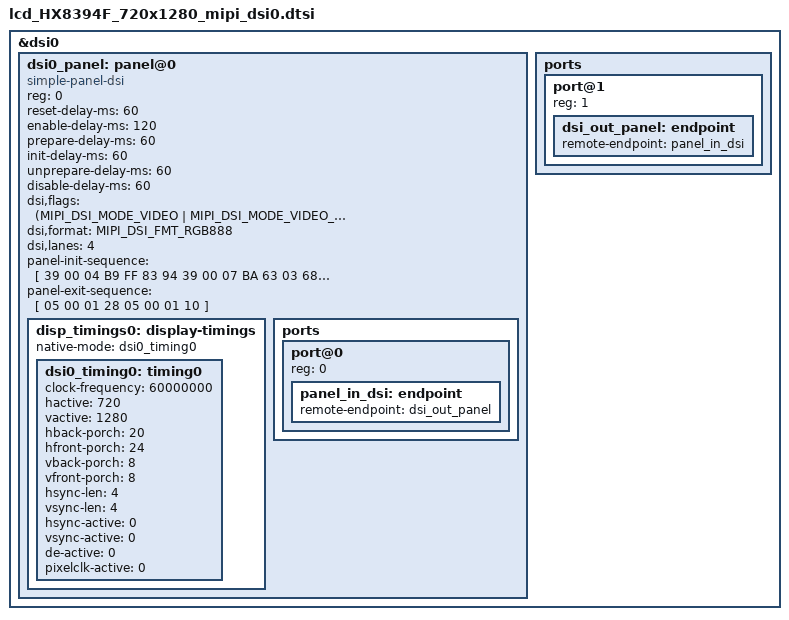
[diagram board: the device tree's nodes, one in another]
#include <dt-bindings/display/drm_mipi_dsi.h>



&dsi0 {
	status = "okay";
	//	rockchip,dual-channel = <&dsi1>;
	
	//rockchip,lane-rate = <1000>;
 	dsi0_panel: panel@0 {
                compatible ="simple-panel-dsi";
                reg = <0>;
		reset-delay-ms = <60>;
		enable-delay-ms = <120>;
		prepare-delay-ms = <60>;
		init-delay-ms = <60>;
		unprepare-delay-ms = <60>;
		disable-delay-ms = <60>;
		
		
		dsi,flags = <(MIPI_DSI_MODE_VIDEO | MIPI_DSI_MODE_VIDEO_BURST |
			MIPI_DSI_MODE_LPM | MIPI_DSI_MODE_EOT_PACKET)>;
		dsi,format = <MIPI_DSI_FMT_RGB888>;
		dsi,lanes  = <4>;
		panel-init-sequence = [
			39 00 04 B9 FF 83 94
			39 00 07 BA 63 03 68 6B B2 C0
			39 00 0B B1 48 12 72 09 32 54 71 71 57 47
			39 00 07 B2 00 80 64 0C 0D 2F
			39 00 16 B4 73 74 73 74 73 74 01 0C 86 75 00 3F 73 74 73 74 73 74 01 0C 86
			39 00 03 B6 6E 6E
			39 00 22 D3 00 00 07 07 40 07 0C 00 08 10 08 00 08 54 15 0A 05 0A 02 15 06 05 06 47 44 0A 0A 4B 10 07 07 0C 40
			39 00 2D D5 1C 1C 1D 1D 00 01 02 03 04 05 06 07 08 09 0A 0B 24 25 18 18 26 27 18 18 18 18 18 18 18 18 18 18 18 18 18 18 18 18 20 21 18 18 18 18 
			39 00 2D D6 1C 1C 1D 1D 07 06 05 04 03 02 01 00 0B 0A 09 08 21 20 18 18 27 26 18 18 18 18 18 18 18 18 18 18 18 18 18 18 18 18 25 24 18 18 18 18
			39 00 3B E0 00 0A 15 1B 1E 21 24 22 47 56 65 66 6E 82 88 8B 9A 9D 98 A8 B9 5D 5C 61 66 6A 6F 7F 7F 00 0A 15 1B 1E 21 24 22 47 56 65 65 6E 81 87 8B 98 9D 99 A8 BA 5D 5D 62 67 6B 72 7F 7F 
			39 00 03 C0 1F 31
			15 00 02 CC 0B
			15 00 02 D4 02
			15 00 02 BD 02
			39 00 0D D8 FF FF FF FF FF FF FF FF FF FF FF FF 
			15 00 02 BD 00
			15 00 02 BD 01
			15 00 02 B1 00
			15 00 02 BD 00
			39 00 08 BF 40 81 50 00 1A FC 01
			15 00 02 C6 ED
			
			05 78 01 11
			05 14 01 29
		];

		panel-exit-sequence = [
			05 00 01 28
			05 00 01 10
		];

		disp_timings0: display-timings {
                        native-mode = <&dsi0_timing0>;
                        dsi0_timing0: timing0 {
				clock-frequency = <60000000>;
				hactive = <720>;
				vactive = <1280>;
				hback-porch = <20>;
				hfront-porch = <24>;
				vback-porch = <8>;
				vfront-porch = <8>;
				hsync-len = <4>;
				vsync-len = <4>;
				hsync-active = <0>;
				vsync-active = <0>;
				de-active = <0>;
				pixelclk-active = <0>;
                    	};
               };

		ports {
			#address-cells = <1>;
			#size-cells = <0>;

			port@0 {
				reg = <0>;
				panel_in_dsi: endpoint {
					remote-endpoint = <&dsi_out_panel>;
				};
			};
		};
	};

	ports {
		#address-cells = <1>;
		#size-cells = <0>;

		port@1 {
			reg = <1>;
			dsi_out_panel: endpoint {
				remote-endpoint = <&panel_in_dsi>;
			};
		};
	};

};
